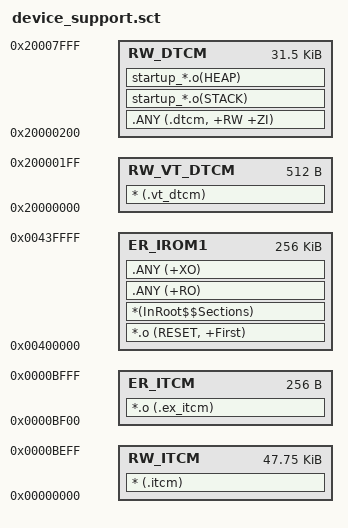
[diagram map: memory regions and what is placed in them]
; *************************************************************
; *** Scatter-Loading Description File generated by uVision ***
; *************************************************************

LR_IROM1 0x00400000 0x00040000  {    ; load region size_region
  ER_IROM1 0x00400000 0x00040000  {  ; load address = execution address
    *.o (RESET, +First)
    *(InRoot$$Sections)
    .ANY (+RO)
    .ANY (+XO)
  }

  RW_ITCM 0x00000000 0x0000BF00  {  ; 47.75K ITCM -> code in sram
    * (.itcm)
  }
  
  ER_ITCM 0x0000BF00 0x00000100  {  ; 256Byte EX_ITCM -> delay* code in sram
    *.o (.ex_itcm)
  }

  RW_VT_DTCM 0x20000000 0x00000200  {  ; 512Byte VT_DTCM -> Vector Table
    * (.vt_dtcm)
  }

  RW_DTCM 0x20000200 0x00007E00  {  ; 31.5K DTCM -> fast sram
    .ANY (.dtcm, +RW +ZI)
    startup_*.o(STACK)
    startup_*.o(HEAP)
  }
}
